# ATxmega16E5 device description
Architecture: AVR8_XMEGA; Family: AVR XMEGA
Registers are 8-bit, access not given, no defined reset value unless marked. A register's access mark holds for its fields unless they carry their own. Offsets are from the block's base; [hi:lo] are bit positions; {n}, {i} and the like mark numbered series.

## GPIO — General Purpose IO Registers
Instances: GPIO 0x0000
{0x0+i} GPIOR{i} (i=0..3) — General Purpose IO Register {i}

## VPORT — Virtual Port
Instances: VPORT{n} {0x10+4n} (n=0..3)
0x00 DIR — I/O Port Data Direction
0x01 OUT — I/O Port Output
0x02 IN — I/O Port Input
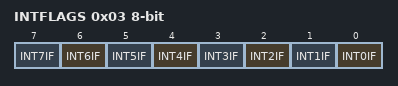
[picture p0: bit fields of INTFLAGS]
0x03 INTFLAGS — Interrupt Flag Register
  [n] INT{n}IF (n=0..7) — Interrupt Pin {n} Flag

## OCD (XOCD module) — On-Chip Debug System
Instances: OCD 0x002E
0x00 OCDR0 — OCD Register 0
  [7:0] OCDRD — OCDR Dirty
0x01 OCDR1 — OCD Register 1
  [0] OCDRD — OCDR Dirty

## CPU — CPU registers
Instances: CPU 0x0030
Parameters: CORE_VERSION=V3XJ
0x04 CCP — Configuration Change Protection
  [7:0] CCP — CCP signature
    157=SPM (SPM Instruction Protection); 216=IOREG (IO Register Protection)
0x08 RAMPD
0x09 RAMPX
0x0A RAMPY
0x0B RAMPZ
0x0C EIND — Extended Indirect Jump
0x0D SPL — Stack Pointer Low
0x0E SPH — Stack Pointer High
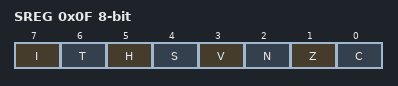
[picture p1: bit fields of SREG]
0x0F SREG — Status Register
  [7] I — Global Interrupt Enable Flag
  [6] T — Transfer Bit
  [5] H — Half Carry Flag
  [4] S — N Exclusive Or V Flag
  [3] V — Two's Complement Overflow Flag
  [2] N — Negative Flag
  [1] Z — Zero Flag
  [0] C — Carry Flag

## CLK — Clock System
Instances: CLK 0x0040
0x00 CTRL — Control Register
  [2:0] SCLKSEL — System Clock Selection
    0=RC2M (Internal 2 MHz RC Oscillator); 1=RC32M (Internal 32 MHz RC Oscillator); 2=RC32K (Internal 32.768 kHz RC Oscillator); 3=XOSC (External Crystal Oscillator or Clock); 4=PLL (Phase Locked Loop); 5=RC8M (Internal 8 MHz RC Oscillator)
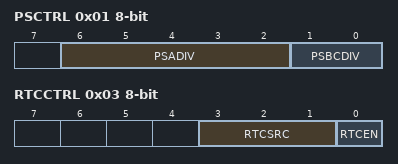
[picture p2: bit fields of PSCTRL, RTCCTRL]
0x01 PSCTRL — Prescaler Control Register
  [6:2] PSADIV — Prescaler A Division Factor
    0=Divide by 1; 1=Divide by 2; 3=Divide by 4; 5=Divide by 8; 7=Divide by 16; 9=Divide by 32; 11=Divide by 64; 13=Divide by 128; 15=Divide by 256; 17=Divide by 512; 19=Divide by 6; 21=Divide by 10; 23=Divide by 12; 25=Divide by 24; 27=Divide by 48
  [1:0] PSBCDIV — Prescaler B and C Division factor
    0=Divide B by 1 and C by 1; 1=1_2 (Divide B by 1 and C by 2); 2=4_1 (Divide B by 4 and C by 1); 3=2_2 (Divide B by 2 and C by 2)
0x02 LOCK
  [0] LOCK — Clock System Lock
0x03 RTCCTRL — RTC Control Register
  [3:1] RTCSRC — Clock Source
    0=ULP (1.024 kHz from internal 32kHz ULP); 1=TOSC (1.024 kHz from 32.768 kHz crystal oscillator on TOSC); 2=RCOSC (1.024 kHz from internal 32.768 kHz RC oscillator); 5=TOSC32 (32.768 kHz from 32.768 kHz crystal oscillator on TOSC); 6=RCOSC32 (32.768 kHz from internal 32.768 kHz RC oscillator); 7=EXTCLK (External Clock from TOSC1)
  [0] RTCEN — Clock Source Enable

## PR — Power Reduction
Instances: PR 0x0070
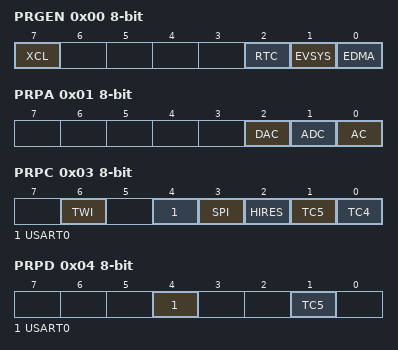
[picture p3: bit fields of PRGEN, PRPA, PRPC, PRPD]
0x00 PRGEN — General Power Reduction
  [7] XCL — XMEGA Custom Logic
  [2] RTC — Real-time Counter
  [1] EVSYS — Event System
  [0] EDMA — Enhanced DMA-Controller
0x01 PRPA — Power Reduction Port A
  [2] DAC — Port A DAC
  [1] ADC — Port A ADC
  [0] AC — Port A Analog Comparator
0x03 PRPC — Power Reduction Port C
  [6] TWI — Port C Two-wire Interface
  [4] USART0 — Port C USART0
  [3] SPI — Port C SPI
  [2] HIRES — Port C WEX
  [1] TC5 — Port C Timer/Counter5
  [0] TC4 — Port C Timer/Counter4
0x04 PRPD — Power Reduction Port D
  [4] USART0 — Port D USART0
  [1] TC5 — Port D Timer/Counter5

## SLEEP — Sleep Controller
Instances: SLEEP 0x0048
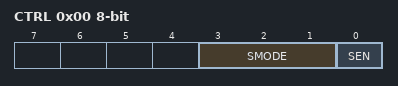
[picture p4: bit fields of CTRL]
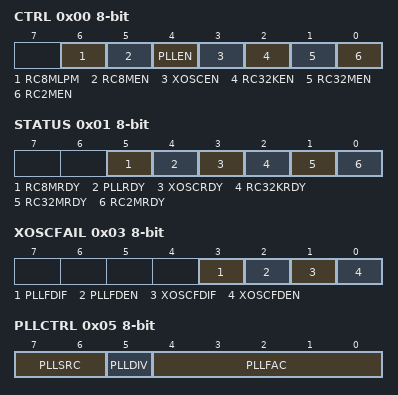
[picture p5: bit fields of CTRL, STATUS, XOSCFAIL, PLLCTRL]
0x00 CTRL — Control Register
  [3:1] SMODE — Sleep Mode
    0=IDLE (Idle mode); 2=PDOWN (Power-down Mode); 3=PSAVE (Power-save Mode); 6=STDBY (Standby Mode); 7=ESTDBY (Extended Standby Mode)
  [0] SEN — Sleep Enable

## OSC — Oscillator
Instances: OSC 0x0050
0x00 CTRL — Control Register
  [6] RC8MLPM — Internal 8 MHz RC Low Power Mode Enable
  [5] RC8MEN — Internal 8 MHz RC Oscillator Enable
  [4] PLLEN — PLL Enable
  [3] XOSCEN — External Oscillator Enable
  [2] RC32KEN — Internal 32.768 kHz RC Oscillator Enable
  [1] RC32MEN — Internal 32 MHz RC Oscillator Enable
  [0] RC2MEN — Internal 2 MHz RC Oscillator Enable
0x01 STATUS
  [5] RC8MRDY — Internal 8 MHz RC Oscillator Ready
  [4] PLLRDY — PLL Ready
  [3] XOSCRDY — External Oscillator Ready
  [2] RC32KRDY — Internal 32.768 kHz RC Oscillator Ready
  [1] RC32MRDY — Internal 32 MHz RC Oscillator Ready
  [0] RC2MRDY — Internal 2 MHz RC Oscillator Ready
0x02 XOSCCTRL — External Oscillator Control Register
  [7:6] FRQRANGE — Frequency Range
    0=04TO2 (0.4 - 2 MHz); 1=2TO9 (2 - 9 MHz); 2=9TO12 (9 - 12 MHz); 3=12TO16 (12 - 16 MHz)
  [5] X32KLPM — 32.768 kHz XTAL OSC Low-power Mode
  [4] XOSCPWR — 16 MHz Crystal Oscillator High Power mode
  [4:0] XOSCSEL — External Oscillator Selection and Startup Time
    0=EXTCLK (External Clock on port R1 - 6 CLK); 2=32KHz (32.768 kHz TOSC - 32K CLK); 3=XTAL_256CLK (0.4-16 MHz XTAL - 256 CLK); 7=XTAL_1KCLK (0.4-16 MHz XTAL - 1K CLK); 11=XTAL_16KCLK (0.4-16 MHz XTAL - 16K CLK); 20=EXTCLK_C4 (External Clock on port C4 - 6 CLK)
0x03 XOSCFAIL — Oscillator Failure Detection Register
  [3] PLLFDIF — PLL Failure Detection Interrupt Flag
  [2] PLLFDEN — PLL Failure Detection Enable
  [1] XOSCFDIF — XOSC Failure Detection Interrupt Flag
  [0] XOSCFDEN — XOSC Failure Detection Enable
0x04 RC32KCAL — 32.768 kHz Internal Oscillator Calibration Register
0x05 PLLCTRL — PLL Control Register
  [7:6] PLLSRC — Clock Source
    0=RC2M (Internal 2 MHz RC Oscillator); 1=RC8M (Internal 8 MHz RC Oscillator); 2=RC32M (Internal 32 MHz RC Oscillator); 3=XOSC (External Oscillator)
  [5] PLLDIV — Divide by 2
  [4:0] PLLFAC — Multiplication Factor
0x06 DFLLCTRL — DFLL Control Register
  [2:1] RC32MCREF — 32 MHz DFLL Calibration Reference
    0=RC32K (Internal 32.768 kHz RC Oscillator); 1=XOSC32K (External 32.768 kHz Crystal Oscillator)
0x07 RC8MCAL — Internal 8 MHz RC Oscillator Calibration Register
  [7:0] RC8MCAL — Calibration Bits
